CM_ "IMPORT _bosch_2018.dbc"

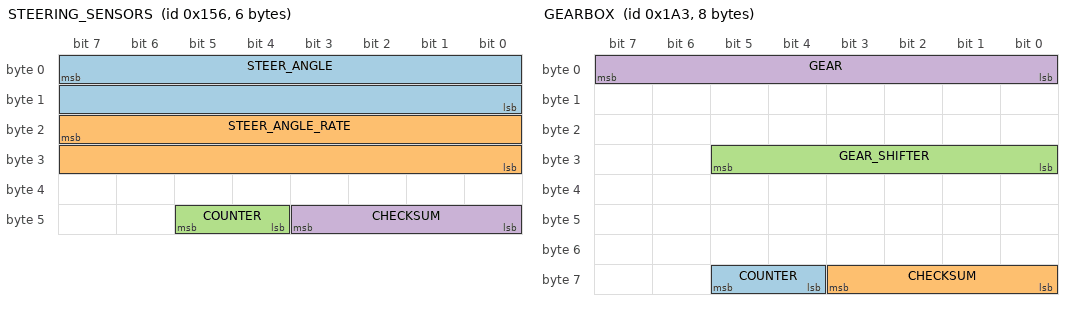
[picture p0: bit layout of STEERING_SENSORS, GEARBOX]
BO_ 342 STEERING_SENSORS: 6 EPS
 SG_ STEER_ANGLE : 7|16@0- (-0.1,0) [-500|500] "deg" EON
 SG_ STEER_ANGLE_RATE : 23|16@0- (1,0) [-3000|3000] "deg/s" EON
 SG_ COUNTER : 45|2@0+ (1,0) [0|3] "" EON
 SG_ CHECKSUM : 43|4@0+ (1,0) [0|15] "" EON

BO_ 419 GEARBOX: 8 PCM
 SG_ COUNTER : 61|2@0+ (1,0) [0|3] "" EON
 SG_ CHECKSUM : 59|4@0+ (1,0) [0|3] "" EON
 SG_ GEAR_SHIFTER : 29|6@0+ (1,0) [0|63] "" EON
 SG_ GEAR : 7|8@0+ (1,0) [0|255] "" EON

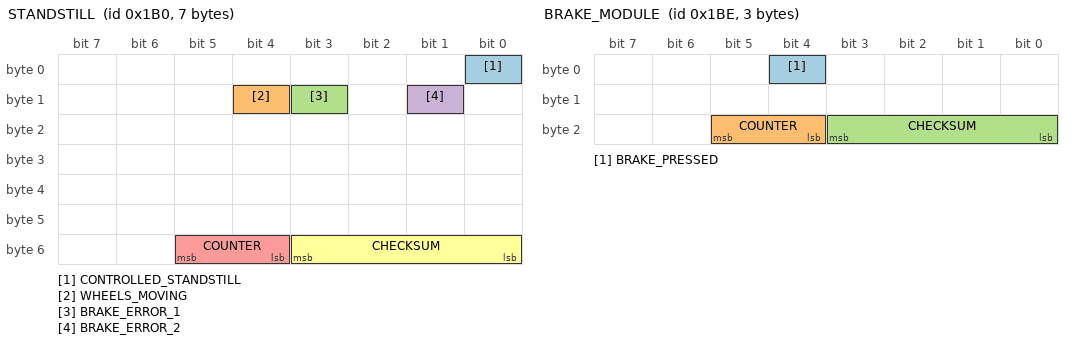
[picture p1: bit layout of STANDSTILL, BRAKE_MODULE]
BO_ 432 STANDSTILL: 7 VSA
 SG_ CONTROLLED_STANDSTILL : 0|1@0+ (1,0) [0|1] "" EON
 SG_ WHEELS_MOVING : 12|1@0+ (1,0) [0|1] "" EON
 SG_ BRAKE_ERROR_1 : 11|1@0+ (1,0) [0|1] "" EON
 SG_ BRAKE_ERROR_2 : 9|1@0+ (1,0) [0|1] "" EON
 SG_ COUNTER : 53|2@0+ (1,0) [0|3] "" EON
 SG_ CHECKSUM : 51|4@0+ (1,0) [0|3] "" EON

BO_ 446 BRAKE_MODULE: 3 VSA
 SG_ BRAKE_PRESSED : 4|1@0+ (1,0) [0|1] "" XXX
 SG_ COUNTER : 21|2@0+ (1,0) [0|3] "" XXX
 SG_ CHECKSUM : 19|4@0+ (1,0) [0|15] "" XXX

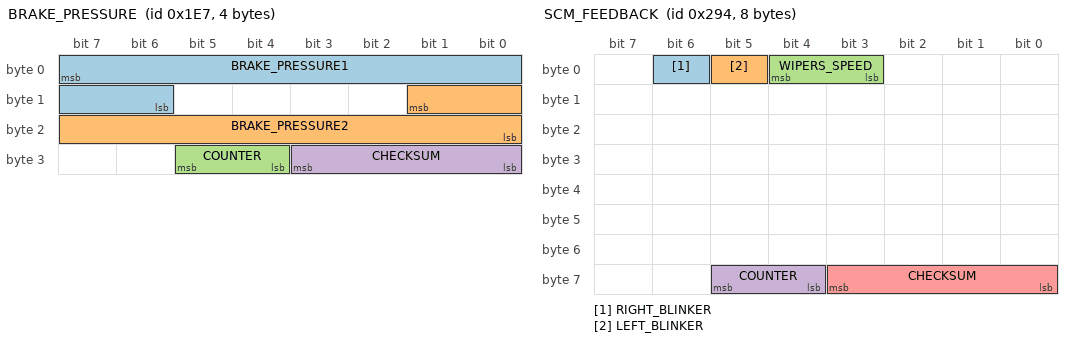
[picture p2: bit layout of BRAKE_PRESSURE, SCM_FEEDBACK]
BO_ 487 BRAKE_PRESSURE: 4 VSA
 SG_ BRAKE_PRESSURE1 : 7|10@0+ (0.015625,-103) [0|1000] "" EON
 SG_ BRAKE_PRESSURE2 : 9|10@0+ (0.015625,-103) [0|1000] "" EON
 SG_ COUNTER : 29|2@0+ (1,0) [0|15] "" EON
 SG_ CHECKSUM : 27|4@0+ (1,0) [0|3] "" EON

BO_ 660 SCM_FEEDBACK: 8 SCM
 SG_ RIGHT_BLINKER : 6|1@0+ (1,0) [0|1] "" EON
 SG_ LEFT_BLINKER : 5|1@0+ (1,0) [0|1] "" EON
 SG_ WIPERS_SPEED : 4|2@0+ (1,0) [0|3] "" EON
 SG_ COUNTER : 61|2@0+ (1,0) [0|3] "" EON
 SG_ CHECKSUM : 59|4@0+ (1,0) [0|15] "" EON

CM_ SG_ 422 PARKING_BRAKE_LIGHT "Believe this is just the dash light for the parking break";
VAL_ 392 GEAR_SHIFTER 0 "S" 1 "P" 2 "R" 4 "N" 8 "D" ;
VAL_ 392 GEAR 26 "S" 4 "D" 3 "N" 2 "R" 1 "P" ;
VAL_ 399 STEER_STATUS 6 "tmp_fault" 5 "fault_1" 4 "no_torque_alert_2" 3 "low_speed_lockout" 2 "no_torque_alert_1" 0 "normal" ;
VAL_ 422 CRUISE_BUTTONS 7 "tbd" 6 "tbd" 5 "tbd" 4 "accel_res" 3 "decel_set" 2 "cancel" 1 "main" 0 "none" ;

CM_ "CHFFR_METRIC 342 STEER_ANGLE STEER_ANGLE 0.36 180; CHFFR_METRIC 380 ENGINE_RPM ENGINE_RPM 1 0; CHFFR_METRIC 804 ENGINE_TEMPERATURE ENGINE_TEMPERATURE 1 0";
